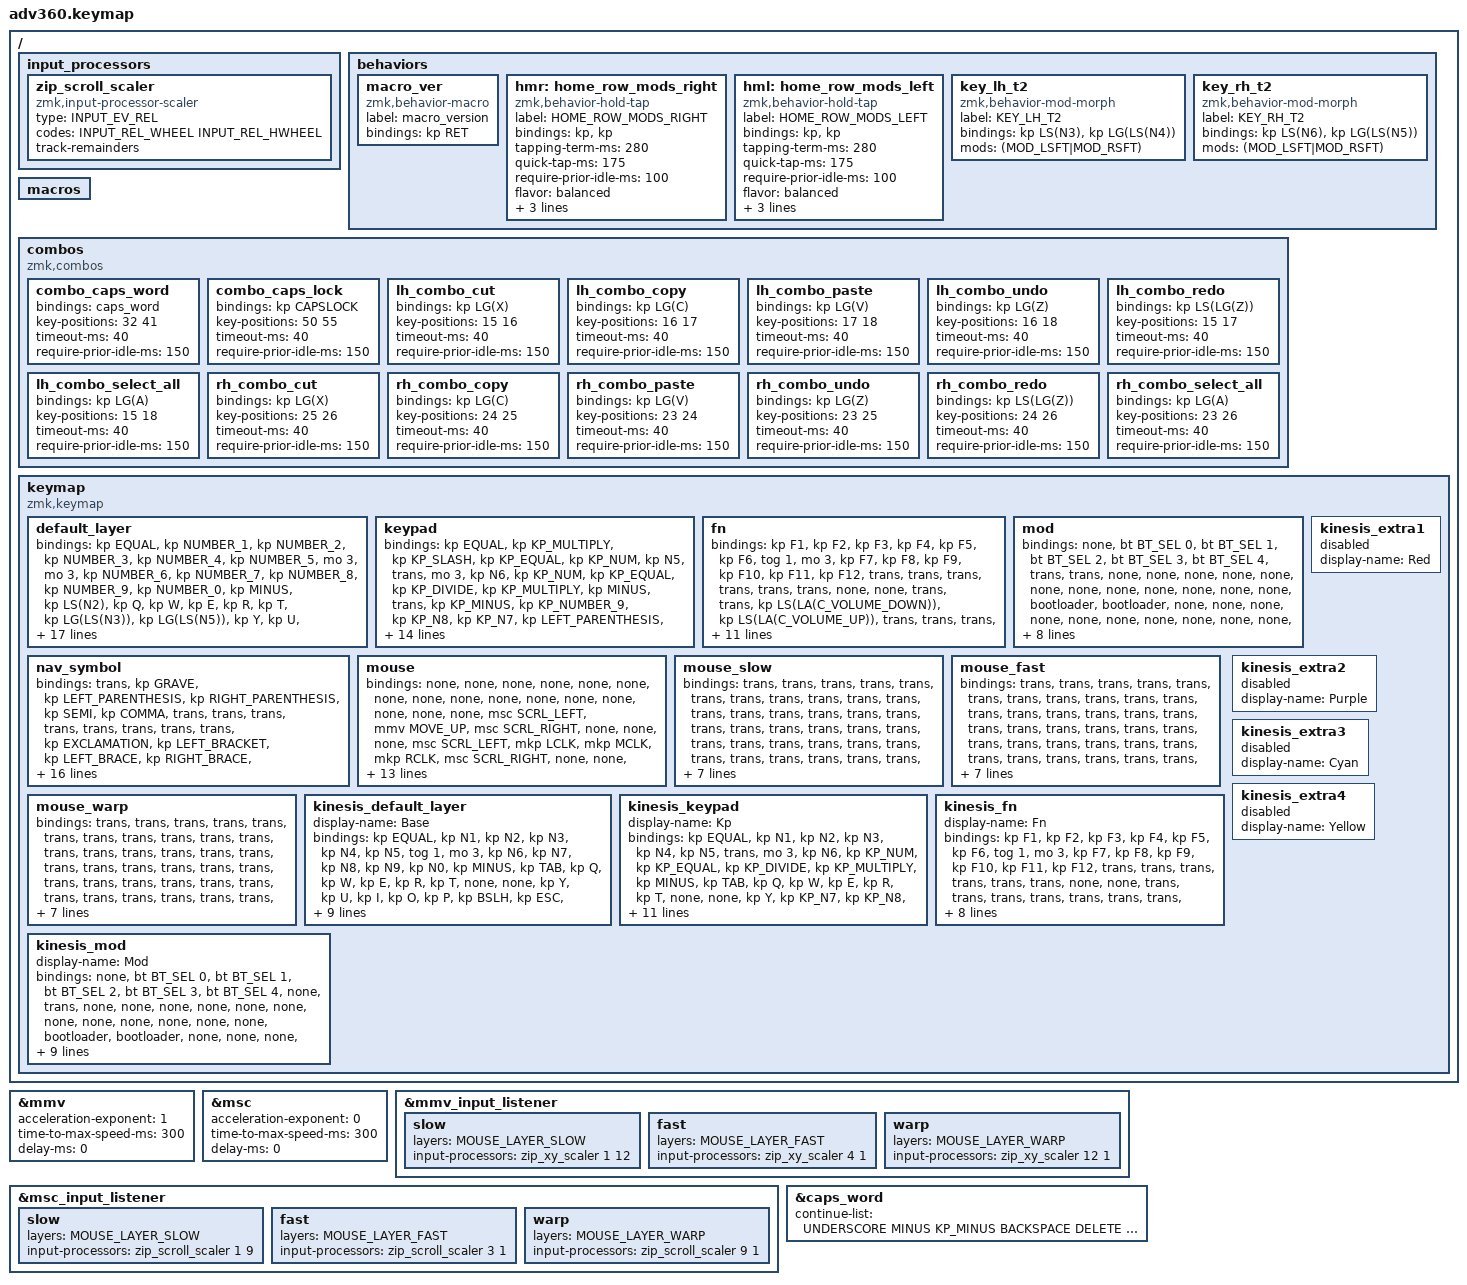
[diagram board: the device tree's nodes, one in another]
#include <dt-bindings/zmk/stp.h>
#include <input/processors.dtsi>
#include <zephyr/dt-bindings/input/input-event-codes.h>
#include <behaviors.dtsi>
#include <dt-bindings/zmk/backlight.h>
#include <dt-bindings/zmk/bt.h>
#include <dt-bindings/zmk/keys.h>
#include <dt-bindings/zmk/pointing.h>
#include <dt-bindings/zmk/rgb.h>

#define MOUSE_LAYER_SLOW 6
#define MOUSE_LAYER_FAST 7
#define MOUSE_LAYER_WARP 8

&mmv {
    acceleration-exponent = <1>;
    time-to-max-speed-ms = <300>;
    delay-ms = <0>;
};

&msc {
    acceleration-exponent = <0>;
    time-to-max-speed-ms = <300>;
    delay-ms = <0>;
};

// Mouse movement speed scaling per layer

&mmv_input_listener {
    slow {
        layers = <MOUSE_LAYER_SLOW>;
        input-processors = <&zip_xy_scaler 1 12>;
    };

    fast {
        layers = <MOUSE_LAYER_FAST>;
        input-processors = <&zip_xy_scaler 4 1>;
    };

    warp {
        layers = <MOUSE_LAYER_WARP>;
        input-processors = <&zip_xy_scaler 12 1>;
    };
};

// Mouse scroll speed scaling per layer

/ {
    input_processors {
        zip_scroll_scaler: zip_scroll_scaler {
            compatible = "zmk,input-processor-scaler";
            #input-processor-cells = <2>;
            type = <INPUT_EV_REL>;
            codes = <INPUT_REL_WHEEL INPUT_REL_HWHEEL>;
            track-remainders;
        };
    };
};

&msc_input_listener {
    slow {
        layers = <MOUSE_LAYER_SLOW>;
        input-processors = <&zip_scroll_scaler 1 9>;
    };

    fast {
        layers = <MOUSE_LAYER_FAST>;
        input-processors = <&zip_scroll_scaler 3 1>;
    };

    warp {
        layers = <MOUSE_LAYER_WARP>;
        input-processors = <&zip_scroll_scaler 9 1>;
    };
};

&caps_word {
    continue-list = <
        UNDERSCORE MINUS KP_MINUS
        BACKSPACE DELETE
        LEFT_SHIFT RIGHT_SHIFT
        N1 N2 N3 N4 N5 N6 N7 N8 N9 N0
        KP_N1 KP_N2 KP_N3 KP_N4 KP_N5 KP_N6 KP_N7 KP_N8 KP_N9 KP_N0
    >;
};

/ {
    behaviors {
        #include "macros.dtsi"
        #include "version.dtsi"

        #ifndef VERSION_MACRO

        macro_ver: macro_ver {
            compatible = "zmk,behavior-macro";
            label = "macro_version";
            #binding-cells = <0>;
            bindings = <&kp RET>;
        };

        #endif

        hmr: home_row_mods_right {
            compatible = "zmk,behavior-hold-tap";
            label = "HOME_ROW_MODS_RIGHT";
            #binding-cells = <2>;
            bindings = <&kp>, <&kp>;

            tapping-term-ms = <280>;
            quick-tap-ms = <175>;
            require-prior-idle-ms = <100>;
            flavor = "balanced";
            hold-trigger-on-release;
            hold-trigger-key-positions = <0 1 2 3 4 5 6 14 15 16 17 18 19 20 28 29 30 31 32 33 34 46 47 48 49 50 51 60 61 62 63 64 35 36 37 38 52 53 65 66 67 68 69 70>;
        };

        hml: home_row_mods_left {
            compatible = "zmk,behavior-hold-tap";
            label = "HOME_ROW_MODS_LEFT";
            #binding-cells = <2>;
            bindings = <&kp>, <&kp>;

            tapping-term-ms = <280>;
            quick-tap-ms = <175>;
            require-prior-idle-ms = <100>;
            flavor = "balanced";
            hold-trigger-on-release;
            hold-trigger-key-positions = <7 8 9 10 11 12 13 21 22 23 24 25 26 27 39 40 41 42 43 44 45 54 55 56 57 58 59 71 72 73 74 75 35 36 37 38 52 53 65 66 67 68 69 70>;
        };

        key_lh_t2: key_lh_t2 {
            compatible = "zmk,behavior-mod-morph";
            label = "KEY_LH_T2";
            bindings = <&kp LS(N3)>, <&kp LG(LS(N4))>;

            #binding-cells = <0>;
            mods = <(MOD_LSFT|MOD_RSFT)>;
        };

        key_rh_t2: key_rh_t2 {
            compatible = "zmk,behavior-mod-morph";
            label = "KEY_RH_T2";
            bindings = <&kp LS(N6)>, <&kp LG(LS(N5))>;

            #binding-cells = <0>;
            mods = <(MOD_LSFT|MOD_RSFT)>;
        };
    };

    macros {
    };

    combos {
        compatible = "zmk,combos";

        combo_caps_word {
            bindings = <&caps_word>;
            key-positions = <32 41>;
            timeout-ms = <40>;
            require-prior-idle-ms = <150>;
        };

        combo_caps_lock {
            bindings = <&kp CAPSLOCK>;
            key-positions = <50 55>;
            timeout-ms = <40>;
            require-prior-idle-ms = <150>;
        };

        // Row above home combos — left hand (Q=15, W=16, E=17, R=18)

        lh_combo_cut {
            bindings = <&kp LG(X)>;
            key-positions = <15 16>;
            timeout-ms = <40>;
            require-prior-idle-ms = <150>;
        };

        lh_combo_copy {
            bindings = <&kp LG(C)>;
            key-positions = <16 17>;
            timeout-ms = <40>;
            require-prior-idle-ms = <150>;
        };

        lh_combo_paste {
            bindings = <&kp LG(V)>;
            key-positions = <17 18>;
            timeout-ms = <40>;
            require-prior-idle-ms = <150>;
        };

        lh_combo_undo {
            bindings = <&kp LG(Z)>;
            key-positions = <16 18>;
            timeout-ms = <40>;
            require-prior-idle-ms = <150>;
        };

        lh_combo_redo {
            bindings = <&kp LS(LG(Z))>;
            key-positions = <15 17>;
            timeout-ms = <40>;
            require-prior-idle-ms = <150>;
        };

        lh_combo_select_all {
            bindings = <&kp LG(A)>;
            key-positions = <15 18>;
            timeout-ms = <40>;
            require-prior-idle-ms = <150>;
        };

        // Row above home combos — right hand mirrored (U=23, I=24, O=25, P=26)

        rh_combo_cut {
            bindings = <&kp LG(X)>;
            key-positions = <25 26>;
            timeout-ms = <40>;
            require-prior-idle-ms = <150>;
        };

        rh_combo_copy {
            bindings = <&kp LG(C)>;
            key-positions = <24 25>;
            timeout-ms = <40>;
            require-prior-idle-ms = <150>;
        };

        rh_combo_paste {
            bindings = <&kp LG(V)>;
            key-positions = <23 24>;
            timeout-ms = <40>;
            require-prior-idle-ms = <150>;
        };

        rh_combo_undo {
            bindings = <&kp LG(Z)>;
            key-positions = <23 25>;
            timeout-ms = <40>;
            require-prior-idle-ms = <150>;
        };

        rh_combo_redo {
            bindings = <&kp LS(LG(Z))>;
            key-positions = <24 26>;
            timeout-ms = <40>;
            require-prior-idle-ms = <150>;
        };

        rh_combo_select_all {
            bindings = <&kp LG(A)>;
            key-positions = <23 26>;
            timeout-ms = <40>;
            require-prior-idle-ms = <150>;
        };
    };

    keymap {
        compatible = "zmk,keymap";

        default_layer {
            bindings = <
&kp EQUAL   &kp NUMBER_1         &kp NUMBER_2     &kp NUMBER_3     &kp NUMBER_4       &kp NUMBER_5                 &mo 3                                                                                             &mo 3           &kp NUMBER_6                 &kp NUMBER_7        &kp NUMBER_8          &kp NUMBER_9       &kp NUMBER_0            &kp MINUS
&kp LS(N2)  &kp Q                &kp W            &kp E            &kp R              &kp T                        &kp LG(LS(N3))                                                                                    &kp LG(LS(N5))  &kp Y                        &kp U               &kp I                 &kp O              &kp P                   &kp BSLH
&kp ESCAPE  &kp A                &kp S            &kp D            &kp F              &hml LS(LA(LC(LEFT_GUI))) G  &kp LG(LS(N4))  &kp GRAVE  &key_lh_t2               &kp EQUAL                    &key_rh_t2       &kp LC(LG(Q))   &hmr LS(LA(LC(LEFT_GUI))) H  &kp J               &kp K                 &kp L              &kp SEMI                &kp SQT
&kp LSHFT   &hml LEFT_CONTROL Z  &hml LEFT_ALT X  &hml LEFT_GUI C  &hml LEFT_SHIFT V  &kp B                                                   &hml LEFT_GUI SPACE      &hmr RIGHT_GUI LS(NUMBER_4)                                   &kp N                        &hmr RIGHT_SHIFT M  &hmr RIGHT_GUI COMMA  &hmr LEFT_ALT DOT  &hmr LEFT_CONTROL FSLH  &kp RSHFT
&mo 2       &kp END              &kp PAGE_UP      &kp PAGE_DOWN    &kp HOME                                        &lt 1 RETURN    &kp TAB    &kp BACKSPACE            &kp RETURN                   &lt 5 BACKSPACE  &lt 4 SPACE                                  &kp LEFT            &kp DOWN              &kp UP             &kp RIGHT               &mo 2
            >;
        };

        keypad {
            bindings = <
&kp EQUAL  &kp KP_MULTIPLY  &kp KP_SLASH     &kp KP_EQUAL  &kp KP_NUM  &kp N5                 &trans                                                       &mo 3      &kp N6                 &kp KP_NUM  &kp KP_EQUAL  &kp KP_DIVIDE  &kp KP_MULTIPLY  &kp MINUS
&trans     &kp KP_MINUS     &kp KP_NUMBER_9  &kp KP_N8     &kp KP_N7   &kp LEFT_PARENTHESIS   &none                                                        &none      &kp LEFT_PARENTHESIS   &kp KP_N7   &kp KP_N8     &kp KP_N9      &kp KP_MINUS     &trans
&trans     &kp KP_PLUS      &kp KP_N6        &kp KP_N5     &kp KP_N4   &kp RIGHT_PARENTHESIS  &none      &trans         &trans      &trans  &trans         &none      &kp RIGHT_PARENTHESIS  &kp KP_N4   &kp KP_N5     &kp KP_N6      &kp KP_PLUS      &trans
&trans     &kp KP_ENTER     &kp KP_N3        &kp KP_N2     &kp KP_N1   &kp PERCENT                                      &trans      &trans                            &kp PERCENT            &kp KP_N1   &kp KP_N2     &kp KP_N3      &kp KP_ENTER     &trans
&mo 2      &kp COLON        &kp KP_DOT       &kp KP_N0     &kp COMMA                          &kp SPACE  &kp BACKSPACE  &trans      &trans  &kp BACKSPACE  &kp SPACE                         &kp COMMA   &kp KP_N0     &kp KP_DOT     &kp COLON        &mo 2
            >;
        };

        fn {
            bindings = <
&kp F1  &kp F2                &kp F3          &kp F4            &kp F5      &kp F6                &tog 1                                      &mo 3   &kp F7  &kp F8      &kp F9                     &kp F10                  &kp F11  &kp F12
&trans  &trans                &trans          &trans            &trans      &trans                &none                                       &none   &trans  &trans      &kp LS(LA(C_VOLUME_DOWN))  &kp LS(LA(C_VOLUME_UP))  &trans   &trans
&trans  &kp C_BRIGHTNESS_DEC  &kp C_PREVIOUS  &kp C_PLAY_PAUSE  &kp C_NEXT  &kp C_BRIGHTNESS_INC  &none   &trans  &trans      &trans  &trans  &none   &trans  &kp C_MUTE  &kp C_VOLUME_DOWN          &kp C_VOLUME_UP          &trans   &trans
&trans  &trans                &trans          &trans            &trans      &tog 5                                &trans      &trans                  &trans  &trans      &trans                     &trans                   &trans   &trans
&trans  &trans                &trans          &trans            &trans                            &trans  &trans  &trans      &trans  &trans  &trans          &trans      &trans                     &trans                   &trans   &trans
            >;
        };

        mod {
            bindings = <
&none  &bt BT_SEL 0  &bt BT_SEL 1  &bt BT_SEL 2  &bt BT_SEL 3  &bt BT_SEL 4  &trans                                                 &trans                  &none  &none       &none       &none  &none  &none
&none  &none         &none         &none         &none         &none         &bootloader                                            &bootloader             &none  &none       &none       &none  &none  &none
&none  &none         &none         &none         &none         &none         &none        &none  &none      &bt BT_CLR  &none       &rgb_ug RGB_MEFS_CMD 5  &none  &none       &none       &none  &none  &none
&none  &none         &none         &none         &macro_ver    &none                             &none      &none                                           &none  &none       &none       &none  &none  &none
&none  &none         &none         &none         &none                       &none        &none  &none      &none       &bl BL_TOG  &rgb_ug RGB_TOG                &bl BL_INC  &bl BL_DEC  &none  &none  &none
            >;
        };

        nav_symbol {
            bindings = <
&trans           &kp GRAVE         &kp LEFT_PARENTHESIS  &kp RIGHT_PARENTHESIS  &kp SEMI           &kp COMMA  &trans                                                            &trans  &trans     &trans             &trans            &trans        &trans            &trans
&kp EXCLAMATION  &kp LEFT_BRACKET  &kp LEFT_BRACE        &kp RIGHT_BRACE        &kp RIGHT_BRACKET  &kp AT     &trans                                                            &trans  &kp DOT    &kp DELETE         &kp LS(TAB)       &kp INSERT    &kp ESCAPE        &trans
&kp POUND        &kp CARET         &kp EQUAL             &kp UNDERSCORE         &kp DOLLAR         &kp STAR   &trans       &kp BACKSLASH  &kp DOT               &trans  &trans  &trans  &kp COMMA  &kp BACKSPACE      &kp TAB           &kp SPACE     &kp ENTER         &trans
&kp TILDE        &kp LESS_THAN     &kp PIPE              &kp MINUS              &kp GREATER_THAN   &kp SLASH                              &triple_backtick      &trans                  &kp SEMI   &kp DOUBLE_QUOTES  &kp SINGLE_QUOTE  &kp GRAVE     &kp BACKSLASH     &trans
&dot_dot         &kp AMPS          &kp SINGLE_QUOTE      &kp DOUBLE_QUOTES      &kp PLUS                      &kp PERCENT  &kp COLON      &kp AT                &trans  &trans  &trans             &kp LEFT_SHIFT     &kp LEFT_GUI      &kp LEFT_ALT  &kp LEFT_CONTROL  &trans
            >;
        };

        mouse {
            bindings = <
&none  &none           &none                  &none           &none            &none           &none                                                      &none      &none           &none           &none           &none                  &none             &none
&none  &none           &msc SCRL_LEFT         &mmv MOVE_UP    &msc SCRL_RIGHT  &none           &none                                                      &none      &msc SCRL_LEFT  &mkp LCLK       &mkp MCLK       &mkp RCLK              &msc SCRL_RIGHT   &none
&none  &msc SCRL_DOWN  &mmv MOVE_LEFT         &mmv MOVE_DOWN  &mmv MOVE_RIGHT  &msc SCRL_DOWN  &none      &mkp MCLK  &kp K_APP      &kp LG(X)  &kp LG(C)  &none      &msc SCRL_DOWN  &tog 7          &tog 8          &tog MOUSE_LAYER_SLOW  &kp K_APP         &mkp LCLK
&none  &msc SCRL_UP    &tog MOUSE_LAYER_SLOW  &tog 8          &tog 7           &msc SCRL_UP                          &mkp LCLK      &none                            &msc SCRL_UP    &mmv MOVE_LEFT  &mmv MOVE_DOWN  &mmv MOVE_UP           &mmv MOVE_RIGHT   &mkp LCLK
&none  &none           &kp LG(X)              &kp LG(C)       &kp LG(V)                        &mkp LCLK  &mkp RCLK  &mkp LCLK      &none      &tog 5     &kp LG(V)                  &kp LEFT_SHIFT  &kp LEFT_GUI    &kp LEFT_ALT           &kp LEFT_CONTROL  &none
            >;
        };

        mouse_slow {
            bindings = <
&trans  &trans  &trans  &trans  &trans  &trans  &trans                                      &trans  &trans  &trans  &trans  &trans  &trans  &trans
&trans  &trans  &trans  &trans  &trans  &trans  &trans                                      &trans  &trans  &trans  &trans  &trans  &trans  &trans
&trans  &trans  &trans  &trans  &trans  &trans  &trans  &trans  &trans      &trans  &trans  &trans  &trans  &trans  &trans  &trans  &trans  &trans
&trans  &trans  &trans  &trans  &trans  &trans                  &trans      &trans                  &trans  &trans  &trans  &trans  &trans  &trans
&trans  &trans  &trans  &trans  &trans          &trans  &trans  &trans      &trans  &trans  &trans          &trans  &trans  &trans  &trans  &trans
            >;
        };

        mouse_fast {
            bindings = <
&trans  &trans  &trans  &trans  &trans  &trans  &trans                                      &trans  &trans  &trans  &trans  &trans  &trans  &trans
&trans  &trans  &trans  &trans  &trans  &trans  &trans                                      &trans  &trans  &trans  &trans  &trans  &trans  &trans
&trans  &trans  &trans  &trans  &trans  &trans  &trans  &trans  &trans      &trans  &trans  &trans  &trans  &trans  &trans  &trans  &trans  &trans
&trans  &trans  &trans  &trans  &trans  &trans                  &trans      &trans                  &trans  &trans  &trans  &trans  &trans  &trans
&trans  &trans  &trans  &trans  &trans          &trans  &trans  &trans      &trans  &trans  &trans          &trans  &trans  &trans  &trans  &trans
            >;
        };

        mouse_warp {
            bindings = <
&trans  &trans  &trans  &trans  &trans  &trans  &trans                                      &trans  &trans  &trans  &trans  &trans  &trans  &trans
&trans  &trans  &trans  &trans  &trans  &trans  &trans                                      &trans  &trans  &trans  &trans  &trans  &trans  &trans
&trans  &trans  &trans  &trans  &trans  &trans  &trans  &trans  &trans      &trans  &trans  &trans  &trans  &trans  &trans  &trans  &trans  &trans
&trans  &trans  &trans  &trans  &trans  &trans                  &trans      &trans                  &trans  &trans  &trans  &trans  &trans  &trans
&trans  &trans  &trans  &trans  &trans          &trans  &trans  &trans      &trans  &trans  &trans          &trans  &trans  &trans  &trans  &trans
            >;
        };

        // Kinesis factory default layers (kept for reference / ZMK Studio)

        kinesis_default_layer {
            display-name = "Base";
            bindings = <
&kp EQUAL  &kp N1     &kp N2    &kp N3    &kp N4     &kp N5  &tog 1                                                   &mo 3      &kp N6  &kp N7  &kp N8     &kp N9    &kp N0    &kp MINUS
&kp TAB    &kp Q      &kp W     &kp E     &kp R      &kp T   &none                                                    &none      &kp Y   &kp U   &kp I      &kp O     &kp P     &kp BSLH
&kp ESC    &kp A      &kp S     &kp D     &kp F      &kp G   &none     &kp LCTRL  &kp LALT      &kp LGUI   &kp RCTRL  &none      &kp H   &kp J   &kp K      &kp L     &kp SEMI  &kp SQT
&kp LSHFT  &kp Z      &kp X     &kp C     &kp V      &kp B                        &kp HOME      &kp PG_UP                        &kp N   &kp M   &kp COMMA  &kp DOT   &kp FSLH  &kp RSHFT
&mo 2      &kp GRAVE  &kp CAPS  &kp LEFT  &kp RIGHT          &kp BSPC  &kp DEL    &kp END       &kp PG_DN  &kp ENTER  &kp SPACE          &kp UP  &kp DOWN   &kp LBKT  &kp RBKT  &mo 2
            >;
        };

        kinesis_keypad {
            display-name = "Kp";
            bindings = <
&kp EQUAL  &kp N1     &kp N2    &kp N3    &kp N4     &kp N5  &trans                                                   &mo 3      &kp N6  &kp KP_NUM  &kp KP_EQUAL  &kp KP_DIVIDE  &kp KP_MULTIPLY  &kp MINUS
&kp TAB    &kp Q      &kp W     &kp E     &kp R      &kp T   &none                                                    &none      &kp Y   &kp KP_N7   &kp KP_N8     &kp KP_N9      &kp KP_MINUS     &kp BSLH
&kp ESC    &kp A      &kp S     &kp D     &kp F      &kp G   &none     &kp LCTRL  &kp LALT      &kp LGUI   &kp RCTRL  &none      &kp H   &kp KP_N4   &kp KP_N5     &kp KP_N6      &kp KP_PLUS      &kp SQT
&kp LSHFT  &kp Z      &kp X     &kp C     &kp V      &kp B                        &kp HOME      &kp PG_UP                        &kp N   &kp KP_N1   &kp KP_N2     &kp KP_N3      &kp KP_ENTER     &kp RSHFT
&mo 2      &kp GRAVE  &kp CAPS  &kp LEFT  &kp RIGHT          &kp BSPC  &kp DEL    &kp END       &kp PG_DN  &kp ENTER  &kp KP_N0          &kp UP      &kp DOWN      &kp KP_DOT     &kp RBKT         &mo 2
            >;
        };

        kinesis_fn {
            display-name = "Fn";
            bindings = <
&kp F1  &kp F2  &kp F3  &kp F4  &kp F5  &kp F6  &tog 1                                      &mo 3   &kp F7  &kp F8  &kp F9  &kp F10  &kp F11  &kp F12
&trans  &trans  &trans  &trans  &trans  &trans  &none                                       &none   &trans  &trans  &trans  &trans   &trans   &trans
&trans  &trans  &trans  &trans  &trans  &trans  &none   &trans  &trans      &trans  &trans  &none   &trans  &trans  &trans  &trans   &trans   &trans
&trans  &trans  &trans  &trans  &trans  &trans                  &trans      &trans                  &trans  &trans  &trans  &trans   &trans   &trans
&trans  &trans  &trans  &trans  &trans          &trans  &trans  &trans      &trans  &trans  &trans          &trans  &trans  &trans   &trans   &trans
            >;
        };

        kinesis_mod {
            display-name = "Mod";
            bindings = <
&none           &bt BT_SEL 0  &bt BT_SEL 1  &bt BT_SEL 2  &bt BT_SEL 3  &bt BT_SEL 4  &none                                                  &trans           &none  &none       &none       &none  &none  &none
&none           &none         &none         &none         &none         &none         &bootloader                                            &bootloader      &none  &none       &none       &none  &none  &none
&studio_unlock  &none         &none         &none         &none         &none         &none        &none  &none      &bt BT_CLR  &none       &stp STP_BAT     &none  &none       &none       &none  &none  &none
&none           &none         &none         &none         &macro_ver    &none                             &none      &none                                    &none  &none       &none       &none  &none  &none
&none           &none         &none         &none         &none                       &none        &none  &none      &none       &bl BL_TOG  &rgb_ug RGB_TOG         &bl BL_INC  &bl BL_DEC  &none  &none  &none
            >;
        };

        kinesis_extra1 {
            display-name = "Red";
            status = "reserved";
        };

        kinesis_extra2 {
            display-name = "Purple";
            status = "reserved";
        };

        kinesis_extra3 {
            display-name = "Cyan";
            status = "reserved";
        };

        kinesis_extra4 {
            display-name = "Yellow";
            status = "reserved";
        };
    };
};
